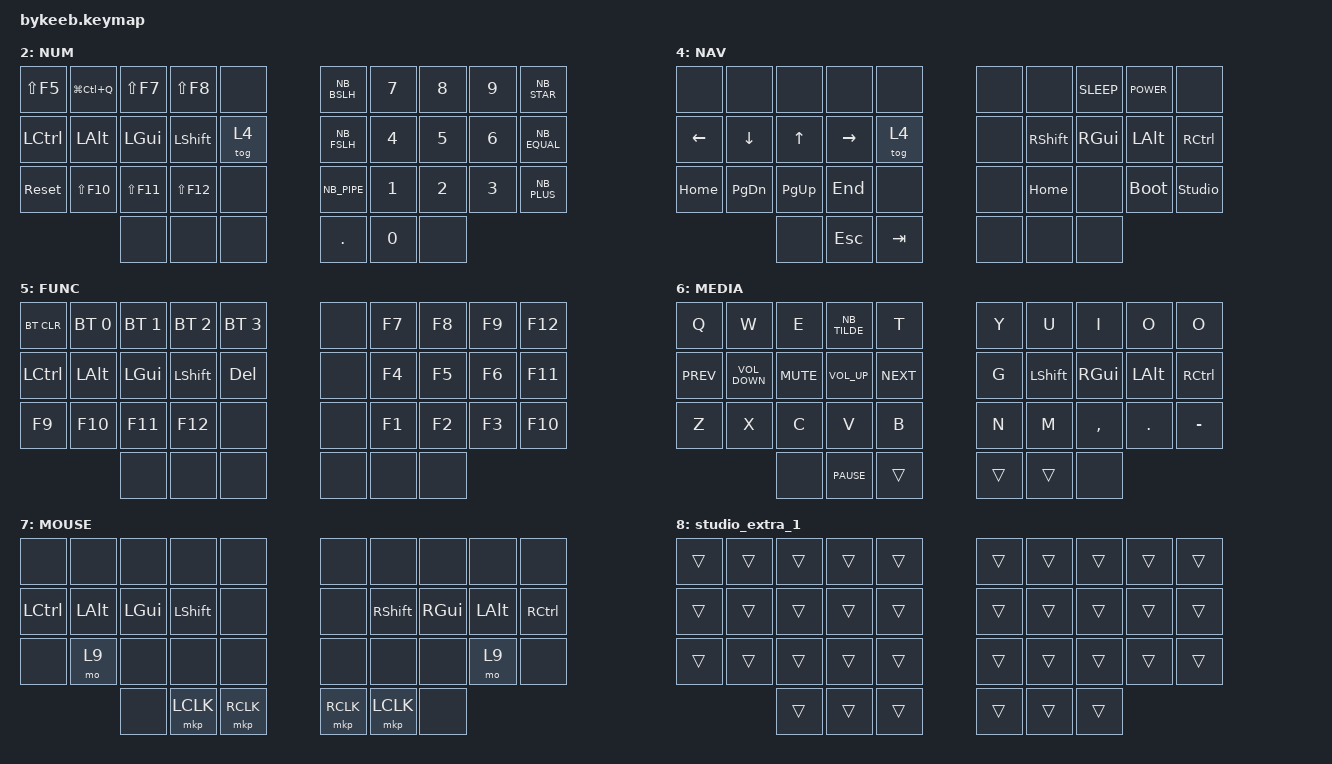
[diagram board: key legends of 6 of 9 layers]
/*
 * Copyright (c) 2024 The ZMK Contributors
 *
 * SPDX-License-Identifier: MIT
 */
#include "keys_nb_osx.h"
#include "keys_nb_win.h"

#include <behaviors.dtsi>
#include <dt-bindings/zmk/keys.h>
#include <dt-bindings/zmk/pointing.h>
#include <dt-bindings/zmk/bt.h>
#include "combos.dtsi"

#define WIN 1
#define SYMBOLS 2
#define NUMBERS 3
#define NAV 4
#define FUNCTION 5
#define BLUETOOTH 6
#define MOUSE 7
#define CLICK 8
#define SCRL 9
#define BIRO 10

&caps_word { 
    continue-list = <NB_UNDERSCORE NB_MINUS WNB_UNDERSCORE WNB_MINUS BACKSPACE DEL>; 
    };

// Change sticky key defaults

&sk {
    release-after-ms = <2000>;
    quick-release;
};

&lt { quick-tap-ms = <175>; };


/ {
        behaviors {
        hml: hml {
            compatible = "zmk,behavior-hold-tap";
            #binding-cells = <2>;
            flavor = "balanced";
            tapping-term-ms = <280>;
            quick-tap-ms = <175>;                // repeat on tap-into-hold
            bindings = <&kp>, <&kp>;
            require-prior-idle-ms = <150>;

            hold-trigger-key-positions = <5 6 7 8 9 15 16 17 18 19 25 26 27 28 29 33 34 31 32>;
            hold-trigger-on-release;
        };

        hmr: hmr {
            compatible = "zmk,behavior-hold-tap";
            #binding-cells = <2>;
            flavor = "balanced";
            tapping-term-ms = <280>;
            quick-tap-ms = <175>;                // repeat on tap-into-hold
            bindings = <&kp>, <&kp>;
            require-prior-idle-ms = <150>;

            hold-trigger-key-positions = <0 1 2 3 4 10 11 12 13 14 20 21 22 23 24 30 31 32 34 33>;
            hold-trigger-on-release;
        };

        lsscw: layer_sticky_shift_caps_word {
            compatible = "zmk,behavior-hold-tap";
            #binding-cells = <2>;
            flavor = "balanced";
            tapping-term-ms = <200>;
            bindings = <&mo>, <&sscw>;
        };

        tt: toggle_layer_tap {
            compatible = "zmk,behavior-hold-tap";
            #binding-cells = <2>;
            tapping-term-ms = <250>;
            flavor = "tap-preferred";
            bindings = <&kp>, <&tog>;
        };

        blt: balanced_layer_tap {
            compatible = "zmk,behavior-hold-tap";
            #binding-cells = <2>;
            tapping-term-ms = <160>;
            quick-tap-ms = <0>;
            flavor = "balanced";
            bindings = <&mo>, <&kp>;
        };

        repeat_encoder: repeat_encoder {
            compatible = "zmk,behavior-sensor-rotate";
            #sensor-binding-cells = <0>;
            bindings = <&kp BSPC>, <&key_repeat>;
        };

        tkp_fast: behavior_trackball_key_press {
            compatible = "zmk,behavior-point-device-directional";
            #trackball-binding-cells = <4>;
            mode = "distance-mode";
            flavor = "2-dim";
            step_size = <50>;
        };

        lt_bspc: layer_tap_bspc_del {
            compatible = "zmk,behavior-hold-tap";
            #binding-cells = <2>;
            bindings = <&mo>, <&bspc_del>;

            tapping-term-ms = <200>;
            quick-tap-ms = <175>;
        };

        shift_layer: shift_layer {
            compatible = "zmk,behavior-hold-tap";
            #binding-cells = <2>;
            bindings = <&mo>, <&sk>;

            tapping-term-ms = <200>;
            flavor = "hold-preferred";
            quick-tap-ms = <100>;
        };

        lt_spcesc: layer_tap_space_esc {
            compatible = "zmk,behavior-hold-tap";
            #binding-cells = <2>;
            bindings = <&mo>, <&spc_esc>;

            tapping-term-ms = <200>;
            quick-tap-ms = <175>;
        };

        apos_dqt: quot_doublequot {
            compatible = "zmk,behavior-mod-morph";
            #binding-cells = <0>;
            bindings = <&kp NB_SINGLE_QUOTE>, <&kp NB_DQT>;

            mods = <(MOD_LSFT|MOD_RSFT)>;
        };

        apos_dqt_win: quot_doublequot_win {
            compatible = "zmk,behavior-mod-morph";
            #binding-cells = <0>;
            bindings = <&kp WNB_APOS>, <&kp WNB_DQT>;

            mods = <(MOD_LSFT|MOD_RSFT)>;
        };

        sscw: sticky_shift_caps_word {
            compatible = "zmk,behavior-mod-morph";
            #binding-cells = <0>;
            bindings = <&sk LSHIFT>, <&caps_word>;

            mods = <(MOD_LSFT|MOD_RSFT)>;
        };

        ques_excl: questionmark_exlamation_mark {
            compatible = "zmk,behavior-mod-morph";
            #binding-cells = <0>;
            bindings = <&kp NB_QMARK>, <&kp NB_EXCL>;

            mods = <(MOD_LSFT|MOD_RSFT)>;
        };

        paras: paras {
            compatible = "zmk,behavior-mod-morph";
            bindings = <&kp NB_LPAR>, <&kp NB_RPAR>;

            #binding-cells = <0>;
            mods = <(MOD_LSFT)>;
        };

        squares: squares {
            compatible = "zmk,behavior-mod-morph";
            bindings = <&kp WNB_LBKT>, <&kp WNB_RBKT>;

            #binding-cells = <0>;
            mods = <(MOD_LSFT)>;
        };

        curles: curles {
            compatible = "zmk,behavior-mod-morph";
            bindings = <&kp NB_LBRC>, <&kp NB_RBRC>;

            #binding-cells = <0>;
            mods = <(MOD_RSFT)>;
        };

        curles_win: curles_win {
            compatible = "zmk,behavior-mod-morph";
            bindings = <&kp WNB_LBRC>, <&kp WNB_RBRC>;

            #binding-cells = <0>;
            mods = <(MOD_RSFT)>;
        };

        crocs: crocs {
            compatible = "zmk,behavior-mod-morph";
            bindings = <&kp NB_GT>, <&kp NB_LT>;

            #binding-cells = <0>;
            mods = <(MOD_RSFT)>;
        };

        shift_space: shift_space {
            compatible = "zmk,behavior-mod-morph";
            bindings = <&kp SPACE>, <&kp ESC>;

            #binding-cells = <0>;
            mods = <(MOD_RSFT)>;
        };

        bspc_del: backspace_delete {
            compatible = "zmk,behavior-mod-morph";
            #binding-cells = <0>;
            bindings = <&kp BACKSPACE>, <&kp DELETE>;

            mods = <(MOD_LSFT|MOD_RSFT)>;
            keep-mods = <(MOD_RSFT)>;
        };

        spc_esc: spc_esc {
            compatible = "zmk,behavior-mod-morph";
            bindings = <&kp SPACE>, <&kp ESC>;

            #binding-cells = <0>;
            mods = <(MOD_RSFT)>;
            keep-mods = <(MOD_RSFT)>;
        };

        hml_shift: hml_shift {
            compatible = "zmk,behavior-hold-tap";
            #binding-cells = <2>;
            flavor = "balanced";
            tapping-term-ms = <200>;
            quick-tap-ms = <175>;
            bindings = <&kp>, <&kp>;

            hold-trigger-key-positions = <5 6 7 8 9 15 16 17 18 19 25 26 27 28 29 33 34 31 32>;
            hold-trigger-on-release;
            label = "HML_SHIFT";
        };

        hmr_shift: hmr_shift {
            compatible = "zmk,behavior-hold-tap";
            #binding-cells = <2>;
            flavor = "balanced";
            tapping-term-ms = <200>;
            quick-tap-ms = <175>;
            bindings = <&kp>, <&kp>;

            hold-trigger-key-positions = <0 1 2 3 4 10 11 12 13 14 20 21 22 23 24 30 31 32 34 33>;
            hold-trigger-on-release;
            label = "HMR_SHIFT";
        };
    };
    keymap {
        compatible = "zmk,keymap";


        default {
            bindings = <
  &kp Q        &kp W        &kp F         &kp P               &kp B         &kp J        &kp L                     &kp U         &kp Y        &apos_dqt
  &hml LCTRL A  &hml LALT R  &hml LGUI S  &hml_shift LSHFT T  &kp G         &kp M        &hmr_shift RIGHT_SHIFT N  &hmr RGUI E  &hmr LALT I  &hmr RCTRL O
  &lt 7 Z      &kp X        &kp C         &kp D               &kp V         &kp K        &kp H                     &kp COMMA     &kp DOT      &lt 7 NB_MINUS
                                       &kp ESC   &lt_spcesc 2 0      &blt 5 TAB    &lt 6 ENTER  &lt_bspc 4 0 &sk LA(LC(LG(LEFT_SHIFT)))
            >;

            display-name = "MAC";
            label = "MAC";
        };

        win {
            bindings = <
  &kp Q        &kp W        &kp F         &kp P           &kp B         &kp J        &kp L               &kp U         &kp Y        &apos_dqt_win
  &hml LCTRL A  &hml LALT R  &hml LGUI S  &hml LSHFT T    &kp G         &kp M        &hmr RIGHT_SHIFT N  &hmr RGUI E  &hmr LALT I  &hmr RCTRL O
  &lt 7 Z      &kp X        &kp C         &kp D           &kp V         &kp K        &kp H               &kp COMMA     &kp DOT      &lt 7 NB_MINUS
                                       &kp ESC   &lt_spcesc 3 0  &blt 5 TAB    &lt 6 ENTER  &lt_bspc 4 0 &sk LA(LC(LG(LEFT_SHIFT)))
            >;

            display-name = "WIN";
            label = "WIN";
        };

        numbers {
            bindings = <
  &kp LS(F5)    &kp LG(LC(Q))  &kp LS(F7)   &kp LS(F8)   &none     &kp NB_BSLH  &kp N7  &kp N8  &kp N9  &kp NB_STAR
  &kp LCTRL  &kp LALT       &kp LGUI    &kp LSHIFT   &tog 4    &kp NB_FSLH  &kp N4  &kp N5  &kp N6  &kp NB_EQUAL
  &sys_reset    &kp LS(F10)    &kp LS(F11)  &kp LS(F12)  &none     &kp NB_PIPE  &kp N1  &kp N2  &kp N3  &kp NB_PLUS
                                         &none   &none        &none     &kp DOT      &kp N0 &none
            >;

            display-name = "NUM";
            label = "NUM";
        };

        num_win {
            bindings = <
  &kp LS(F5)    &kp LG(L)    &kp RIGHT_ALT  &kp LS(F8)  &none     &kp WNB_BSLH  &kp N7  &kp N8  &kp N9  &kp WNB_STAR
  &kp LCTRL  &kp LALT     &kp LGUI      &kp LSHIFT  &tog 4    &kp WNB_FSLH  &kp N4  &kp N5  &kp N6  &kp WNB_EQUAL
  &studio_unlock    &bootloader  &kp LS(F11)    &kp RALT    &none     &kp WNB_PIPE  &kp N1  &kp N2  &kp N3  &kp WNB_PLUS
                                            &none       &none     &kp DOT       &kp N0  &none
            >;

            display-name = "NUM";
            label = "NUW";
        };

        nav {
            bindings = <
  &none     &none  &none  &none  &none      &none  &none            &kp C_SLEEP  &kp C_POWER  &none
  &kp LEFT  &kp DOWN      &kp UP        &kp RIGHT     &tog 4     &none  &kp RIGHT_SHIFT  &kp RGUI    &kp LALT     &kp RCTRL
  &kp HOME  &kp PG_DN     &kp PG_UP     &kp END       &none      &none  &kp HOME         &none        &bootloader     &studio_unlock
                                   &none     &kp ESC       &kp TAB    &none  &none &none
            >;

            display-name = "NAV";
            label = "NAV";
        };

        fn {
            bindings = <
  &bt BT_CLR    &bt BT_SEL 0    &bt BT_SEL 1     &bt BT_SEL 2      &bt BT_SEL 3   &none  &kp F7  &kp F8  &kp F9  &kp F12
  &kp LCTRL  &kp LALT  &kp LGUI  &kp LSHIFT  &kp DEL    &none  &kp F4  &kp F5  &kp F6  &kp F11
  &kp F9    &kp F10   &kp F11    &kp F12     &none      &none  &kp F1  &kp F2  &kp F3  &kp F10
                             &none    &none       &none      &none  &none &none
            >;

            display-name = "FUNC";
            label = "FUN";
        };

        controls {
            bindings = <
  &kp Q       &kp W              &kp E       &kp NB_TILDE     &kp T         &kp Y   &kp U      &kp I      &kp O     &kp O
  &kp C_PREV  &kp C_VOLUME_DOWN  &kp C_MUTE  &kp C_VOLUME_UP  &kp C_NEXT    &kp G   &kp LSHFT  &kp RGUI  &kp LALT  &kp RCTRL
  &kp Z       &kp X              &kp C       &kp V            &kp B         &kp N   &kp M      &kp COMMA  &kp DOT   &kp MINUS
                                        &none     &kp C_PAUSE      &trans        &trans  &trans &none
            >;

            display-name = "MEDIA";
            label = "MED";
        };

        mouse {
            bindings = <
  &none          &none         &none      &none           &none        &none      &none            &none      &none         &none
  &kp LCTRL  &kp LEFT_ALT  &kp LGUI  &kp LEFT_SHIFT  &none        &none      &kp RIGHT_SHIFT  &kp RGUI  &kp LEFT_ALT  &kp RCTRL
  &none          &mo 9         &none      &none           &none        &none      &none            &none      &mo 9         &none
                                      &none    &mkp LCLK       &mkp RCLK    &mkp RCLK  &mkp LCLK &none
            >;

            display-name = "MOUSE";
            label = "MOUS";
        };

        studio_extra_1 {
            bindings = <
    &trans  &trans  &trans  &trans  &trans                  &trans  &trans  &trans  &trans  &trans
    &trans  &trans  &trans  &trans  &trans                  &trans  &trans  &trans  &trans  &trans
    &trans  &trans  &trans  &trans  &trans                  &trans  &trans  &trans  &trans  &trans
                    &trans  &trans  &trans                  &trans  &trans  &trans
            >;
        };
    };
};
